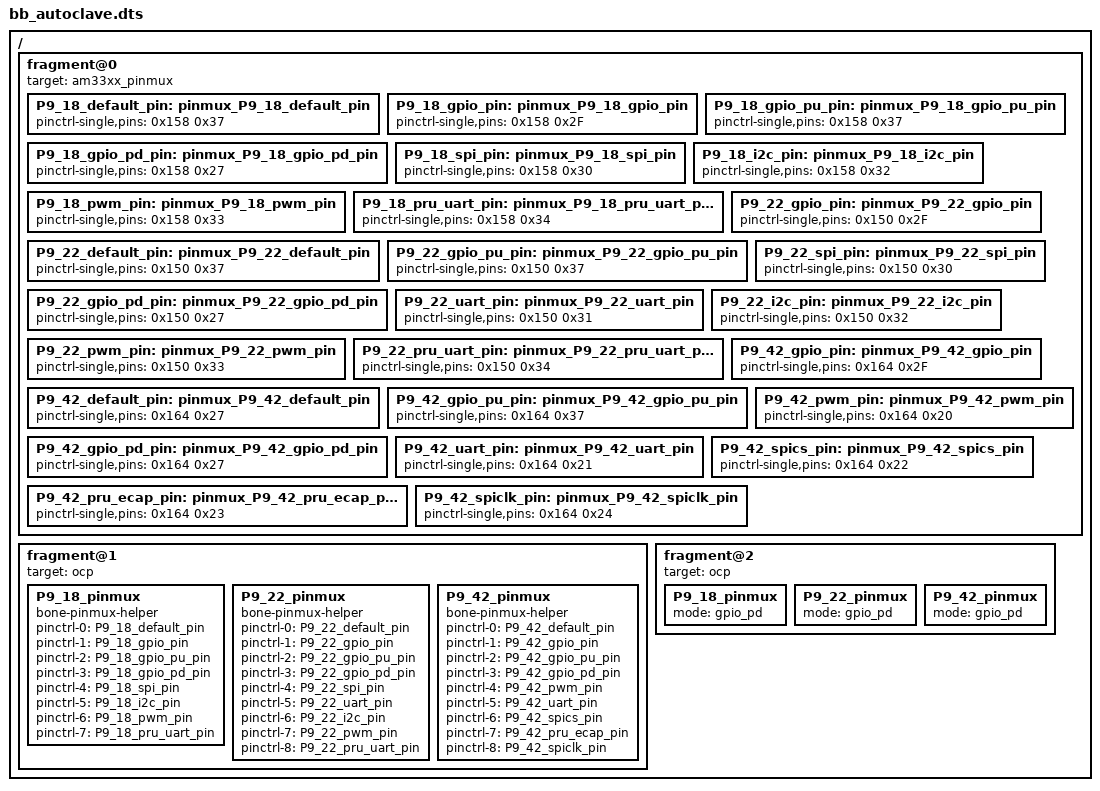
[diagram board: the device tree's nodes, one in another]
/*
 * Autoclave BeagleBone overlay:  configure output pins

 * sudo dtc -O dtb -o /lib/firmware/bb_autoclave-00A0.dtbo -b 0 -@ bb_autoclave.dts
 * - Ignore 3x "Warning (unit_address_vs_reg)"
 * echo dtb_overlay=/lib/firmware/bb_autoclave-00A0.dtbo | sudo tee -a /boot/uEnv.txt
 * for i in 18 22; do config-pin -q P9.$i; done

 */

/dts-v1/;
/plugin/;

/{  
    fragment@0 {
        target = <&am33xx_pinmux>;
	/* P9_18 (ZCZ ball B16) */
	P9_18_default_pin: pinmux_P9_18_default_pin {
	    pinctrl-single,pins = <0x158  0x37>; };     /* Mode 7, Pull-Up, RxActive */
	P9_18_gpio_pin: pinmux_P9_18_gpio_pin {
	    pinctrl-single,pins = <0x158  0x2F>; };     /* Mode 7, RxActive */
	P9_18_gpio_pu_pin: pinmux_P9_18_gpio_pu_pin {
	    pinctrl-single,pins = <0x158  0x37>; };     /* Mode 7, Pull-Up, RxActive */
	P9_18_gpio_pd_pin: pinmux_P9_18_gpio_pd_pin {
	    pinctrl-single,pins = <0x158  0x27>; };     /* Mode 7, Pull-Down, RxActive */
	P9_18_spi_pin: pinmux_P9_18_spi_pin {
	    pinctrl-single,pins = <0x158  0x30>; };     /* Mode 0, Pull-Up, RxActive */
	P9_18_i2c_pin: pinmux_P9_18_i2c_pin {
	    pinctrl-single,pins = <0x158  0x32>; };     /* Mode 2, Pull-Up, RxActive */
	P9_18_pwm_pin: pinmux_P9_18_pwm_pin {
	    pinctrl-single,pins = <0x158  0x33>; };     /* Mode 3, Pull-Up, RxActive */
	P9_18_pru_uart_pin: pinmux_P9_18_pru_uart_pin {
	    pinctrl-single,pins = <0x158 0x34>; }; /* Mode 4, Pull-Up, RxActive */

	/* P9_22 (ZCZ ball A17) */
	P9_22_default_pin: pinmux_P9_22_default_pin {
	    pinctrl-single,pins = <0x150  0x37>; };     /* Mode 7, Pull-Up, RxActive */
	P9_22_gpio_pin: pinmux_P9_22_gpio_pin {
	    pinctrl-single,pins = <0x150  0x2F>; };     /* Mode 7, RxActive */
	P9_22_gpio_pu_pin: pinmux_P9_22_gpio_pu_pin {
	    pinctrl-single,pins = <0x150  0x37>; };     /* Mode 7, Pull-Up, RxActive */
	P9_22_gpio_pd_pin: pinmux_P9_22_gpio_pd_pin {
	    pinctrl-single,pins = <0x150  0x27>; };     /* Mode 7, Pull-Down, RxActive */
	P9_22_spi_pin: pinmux_P9_22_spi_pin {
	    pinctrl-single,pins = <0x150  0x30>; };     /* Mode 0, Pull-Up, RxActive */
	P9_22_uart_pin: pinmux_P9_22_uart_pin {
	    pinctrl-single,pins = <0x150  0x31>; };     /* Mode 1, Pull-Up, RxActive */
	P9_22_i2c_pin: pinmux_P9_22_i2c_pin {
	    pinctrl-single,pins = <0x150  0x32>; };     /* Mode 2, Pull-Up, RxActive */
	P9_22_pwm_pin: pinmux_P9_22_pwm_pin {
	    pinctrl-single,pins = <0x150  0x33>; };     /* Mode 3, Pull-Up, RxActive */
	P9_22_pru_uart_pin: pinmux_P9_22_pru_uart_pin {
	    pinctrl-single,pins = <0x150  0x34>; };     /* Mode 4, Pull-Up, RxActive */

	/* P9_42 (ZCZ ball C18) */
	P9_42_default_pin: pinmux_P9_42_default_pin {
	    pinctrl-single,pins = <0x164  0x27>; };     /* Mode 7, Pull-Down, RxActive */
	P9_42_gpio_pin: pinmux_P9_42_gpio_pin {
	    pinctrl-single,pins = <0x164  0x2F>; };     /* Mode 7, RxActive */
	P9_42_gpio_pu_pin: pinmux_P9_42_gpio_pu_pin {
	    pinctrl-single,pins = <0x164  0x37>; };     /* Mode 7, Pull-Up, RxActive */
	P9_42_gpio_pd_pin: pinmux_P9_42_gpio_pd_pin {
	    pinctrl-single,pins = <0x164  0x27>; };     /* Mode 7, Pull-Down, RxActive */
	P9_42_pwm_pin: pinmux_P9_42_pwm_pin {
	    pinctrl-single,pins = <0x164  0x20>; };     /* Mode 0, Pull-Down, RxActive */
	P9_42_uart_pin: pinmux_P9_42_uart_pin {
	    pinctrl-single,pins = <0x164  0x21>; };     /* Mode 1, Pull-Down, RxActive */
	P9_42_spics_pin: pinmux_P9_42_spics_pin {
	    pinctrl-single,pins = <0x164  0x22>; };     /* Mode 2, Pull-Down, RxActive */
	P9_42_pru_ecap_pin: pinmux_P9_42_pru_ecap_pin {
	    pinctrl-single,pins = <0x164  0x23>; };     /* Mode 3, Pull-Down, RxActive */
	P9_42_spiclk_pin: pinmux_P9_42_spiclk_pin {
	    pinctrl-single,pins = <0x164  0x24>; };     /* Mode 4, Pull-Down, RxActive */

    };

    fragment@1 {
        target = <&ocp>;
	P9_18_pinmux {
	    compatible = "bone-pinmux-helper";
	    status = "okay";
	    pinctrl-names = "default", "gpio", "gpio_pu", "gpio_pd", "spi", "i2c", "pwm", "pru_uart";
	    pinctrl-0 = <&P9_18_default_pin>;
	    pinctrl-1 = <&P9_18_gpio_pin>;
	    pinctrl-2 = <&P9_18_gpio_pu_pin>;
	    pinctrl-3 = <&P9_18_gpio_pd_pin>;
	    pinctrl-4 = <&P9_18_spi_pin>;
	    pinctrl-5 = <&P9_18_i2c_pin>;
	    pinctrl-6 = <&P9_18_pwm_pin>;
	    pinctrl-7 = <&P9_18_pru_uart_pin>;
	};

	P9_22_pinmux {
	    compatible = "bone-pinmux-helper";
	    status = "okay";
	    pinctrl-names = "default", "gpio", "gpio_pu", "gpio_pd", "spi", "uart", "i2c", "pwm", "pru_uart";
	    pinctrl-0 = <&P9_22_default_pin>;
	    pinctrl-1 = <&P9_22_gpio_pin>;
	    pinctrl-2 = <&P9_22_gpio_pu_pin>;
	    pinctrl-3 = <&P9_22_gpio_pd_pin>;
	    pinctrl-4 = <&P9_22_spi_pin>;
	    pinctrl-5 = <&P9_22_uart_pin>;
	    pinctrl-6 = <&P9_22_i2c_pin>;
	    pinctrl-7 = <&P9_22_pwm_pin>;
	    pinctrl-8 = <&P9_22_pru_uart_pin>;
	};

	P9_42_pinmux {
	    compatible = "bone-pinmux-helper";
	    status = "okay";
	    pinctrl-names = "default", "gpio", "gpio_pu", "gpio_pd", "pwm", "uart", "spics", "pru_ecap", "spiclk";
	    pinctrl-0 = <&P9_42_default_pin>;
	    pinctrl-1 = <&P9_42_gpio_pin>;
	    pinctrl-2 = <&P9_42_gpio_pu_pin>;
	    pinctrl-3 = <&P9_42_gpio_pd_pin>;
	    pinctrl-4 = <&P9_42_pwm_pin>;
	    pinctrl-5 = <&P9_42_uart_pin>;
	    pinctrl-6 = <&P9_42_spics_pin>;
	    pinctrl-7 = <&P9_42_pru_ecap_pin>;
	    pinctrl-8 = <&P9_42_spiclk_pin>;
	};
    };

    fragment@2 {
	target = <&ocp>;
	P9_18_pinmux { /* Valve SSR */
	    mode = "gpio_pd";
	};
	P9_22_pinmux { /* Burner SSR */
	    mode = "gpio_pd";
	};
	P9_42_pinmux { /* Estop in */
	    mode = "gpio_pd";
	};
    };
};
